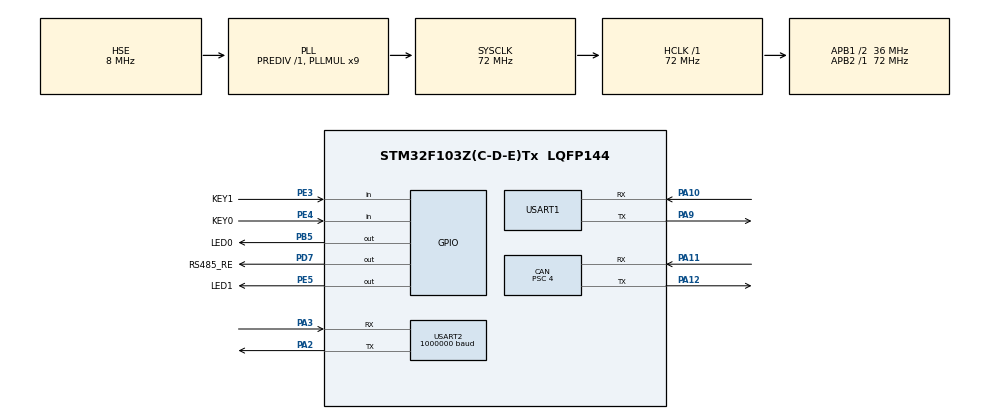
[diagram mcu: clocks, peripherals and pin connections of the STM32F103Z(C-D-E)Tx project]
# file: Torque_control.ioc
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CAN.ABOM=ENABLE
CAN.BS1=CAN_BS1_7TQ
CAN.CalculateBaudRate=1000000
CAN.CalculateTimeBit=1000
CAN.CalculateTimeQuantum=111.11111111111111
CAN.NART=ENABLE
CAN.Prescaler=4
Dma.Request0=USART2_RX
Dma.USART2_RX.0.Direction=DMA_PERIPH_TO_MEMORY
Dma.USART2_RX.0.Instance=DMA1_Channel6
Dma.USART2_RX.0.MemDataAlignment=DMA_MDATAALIGN_BYTE
Dma.USART2_RX.0.MemInc=DMA_MINC_ENABLE
Dma.USART2_RX.0.Mode=DMA_NORMAL
Dma.USART2_RX.0.PeriphDataAlignment=DMA_PDATAALIGN_BYTE
Dma.USART2_RX.0.PeriphInc=DMA_PINC_DISABLE
Dma.USART2_RX.0.Priority=DMA_PRIORITY_LOW
Mcu.Family=STM32F1
Mcu.Name=STM32F103Z(C-D-E)Tx
Mcu.Package=LQFP144
NVIC.DMA1_Channel6_IRQn=true\:0\:0\:false\:false\:true\:false\:true\:true
NVIC.PriorityGroup=NVIC_PRIORITYGROUP_4
NVIC.TIM3_IRQn=true\:1\:0\:true\:false\:true\:true\:true\:true
NVIC.USART1_IRQn=true\:1\:0\:true\:false\:true\:true\:true\:true
NVIC.USART2_IRQn=true\:0\:0\:true\:false\:true\:false\:true\:true
NVIC.USB_LP_CAN1_RX0_IRQn=true\:0\:0\:true\:false\:true\:true\:true\:true
OSC_IN.Mode=HSE-External-Oscillator
OSC_IN.Signal=RCC_OSC_IN
OSC_OUT.Mode=HSE-External-Oscillator
OSC_OUT.Signal=RCC_OSC_OUT
PA10.Mode=Asynchronous
PA10.Signal=USART1_RX
PA11.Mode=CAN_Activate
PA11.Signal=CAN_RX
PA12.Mode=CAN_Activate
PA12.Signal=CAN_TX
PA13.Mode=Serial_Wire
PA13.Signal=SYS_JTMS-SWDIO
PA14.Mode=Serial_Wire
PA14.Signal=SYS_JTCK-SWCLK
PA2.Mode=Asynchronous
PA2.Signal=USART2_TX
PA3.Mode=Asynchronous
PA3.Signal=USART2_RX
PA9.Mode=Asynchronous
PA9.Signal=USART1_TX
PB5.GPIO_Label=LED0
PB5.GPIO_PuPd=GPIO_PULLUP
PB5.PinState=GPIO_PIN_SET
PB5.Signal=GPIO_Output
PC14-OSC32_IN.Mode=LSE-External-Oscillator
PC14-OSC32_IN.Signal=RCC_OSC32_IN
PC15-OSC32_OUT.Mode=LSE-External-Oscillator
PC15-OSC32_OUT.Signal=RCC_OSC32_OUT
PD7.GPIO_Label=RS485_RE
PD7.GPIO_PuPd=GPIO_PULLDOWN
PD7.Signal=GPIO_Output
PE3.GPIO_Label=KEY1
PE3.GPIO_Mode=GPIO_MODE_INPUT
PE3.GPIO_PuPd=GPIO_PULLUP
PE3.Signal=GPIO_Input
PE4.GPIO_Label=KEY0
PE4.GPIO_PuPd=GPIO_PULLUP
PE4.Signal=GPIO_Input
PE5.GPIO_Label=LED1
PE5.GPIO_PuPd=GPIO_PULLUP
PE5.PinState=GPIO_PIN_SET
PE5.Signal=GPIO_Output
ProjectManager.HeapSize=0x200
ProjectManager.StackSize=0x400
ProjectManager.TargetToolchain=MDK-ARM V5.32
RCC.AHBFreq_Value=72000000
RCC.APB1CLKDivider=RCC_HCLK_DIV2
RCC.APB1Freq_Value=36000000
RCC.APB1TimFreq_Value=72000000
RCC.APB2Freq_Value=72000000
RCC.APB2TimFreq_Value=72000000
RCC.HCLKFreq_Value=72000000
RCC.PLLMUL=RCC_PLL_MUL9
RCC.PLLSourceVirtual=RCC_PLLSOURCE_HSE
RCC.SYSCLKFreq_VALUE=72000000
RCC.SYSCLKSource=RCC_SYSCLKSOURCE_PLLCLK
RCC.USBFreq_Value=72000000
TIM3.AutoReloadPreload=TIM_AUTORELOAD_PRELOAD_ENABLE
TIM3.Period=10000-1
TIM3.Prescaler=72-1
USART1.VirtualMode=VM_ASYNC
USART2.BaudRate=1000000
USART2.VirtualMode=VM_ASYNC
USART2.WordLength=WORDLENGTH_8B
VP_TIM3_VS_ClockSourceINT.Mode=Internal
board=custom

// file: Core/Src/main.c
/* USER CODE BEGIN Header */
/**
  ******************************************************************************
  * @file           : main.c
  * @brief          : Main program body
  ******************************************************************************
  * @attention
  *
  * Copyright (c) 2026 STMicroelectronics.
  * All rights reserved.
  *
  * This software is licensed under terms that can be found in the LICENSE file
  * in the root directory of this software component.
  * If no LICENSE file comes with this software, it is provided AS-IS.
  *
  ******************************************************************************
  */
/* USER CODE END Header */
#include "main.h"
#include "can.h"
#include "dma.h"
#include "tim.h"
#include "usart.h"
#include "gpio.h"

/* USER CODE BEGIN Includes */
#include "app_user.h"
#include "app_nj70.h"
#include "app_joint.h"
/* USER CODE END Includes */

void SystemClock_Config(void);

int main(void)
{

  /* MCU Configuration--------------------------------------------------------*/

  /* Reset of all peripherals, Initializes the Flash interface and the Systick. */
  HAL_Init();

  /* Configure the system clock */
  SystemClock_Config();

  /* Initialize all configured peripherals */
  MX_GPIO_Init();
  MX_DMA_Init();
  MX_USART2_UART_Init();
  MX_USART1_UART_Init();
  MX_CAN_Init();
  MX_TIM3_Init();
  /* USER CODE BEGIN 2 */
	Bsp_Can_Init();
	Dev_Joint_Init(1);
	Dev_NJ70_Init(rx_buffer, MAX_RX_BUFFER_SIZE);
  /* USER CODE END 2 */

  /* Infinite loop */
  /* USER CODE BEGIN WHILE */
  while (1)
  {
		App_Led_Task();
		App_Key_Task();
		App_NJ70_Task();
		App_Joint_Task();
		App_Joint_Adm_Task();        /* 导纳环：状态机 + PP 换点 + 发帧（ISR 里只算控制量） */
		//App_Joint_GravScan_Task(); /* PP 8 点扫角，标定重力矩时打开 */

    /* USER CODE END WHILE */

  }
}

void SystemClock_Config(void)
{
  RCC_OscInitTypeDef RCC_OscInitStruct = {0};
  RCC_ClkInitTypeDef RCC_ClkInitStruct = {0};

  /** Initializes the RCC Oscillators according to the specified parameters
  * in the RCC_OscInitTypeDef structure.
  */
  RCC_OscInitStruct.OscillatorType = RCC_OSCILLATORTYPE_HSE;
  RCC_OscInitStruct.HSEState = RCC_HSE_ON;
  RCC_OscInitStruct.HSEPredivValue = RCC_HSE_PREDIV_DIV1;
  RCC_OscInitStruct.HSIState = RCC_HSI_ON;
  RCC_OscInitStruct.PLL.PLLState = RCC_PLL_ON;
  RCC_OscInitStruct.PLL.PLLSource = RCC_PLLSOURCE_HSE;
  RCC_OscInitStruct.PLL.PLLMUL = RCC_PLL_MUL9;
  if (HAL_RCC_OscConfig(&RCC_OscInitStruct) != HAL_OK)
  {
    Error_Handler();
  }

  /** Initializes the CPU, AHB and APB buses clocks
  */
  RCC_ClkInitStruct.ClockType = RCC_CLOCKTYPE_HCLK|RCC_CLOCKTYPE_SYSCLK
                              |RCC_CLOCKTYPE_PCLK1|RCC_CLOCKTYPE_PCLK2;
  RCC_ClkInitStruct.SYSCLKSource = RCC_SYSCLKSOURCE_PLLCLK;
  RCC_ClkInitStruct.AHBCLKDivider = RCC_SYSCLK_DIV1;
  RCC_ClkInitStruct.APB1CLKDivider = RCC_HCLK_DIV2;
  RCC_ClkInitStruct.APB2CLKDivider = RCC_HCLK_DIV1;

  if (HAL_RCC_ClockConfig(&RCC_ClkInitStruct, FLASH_LATENCY_2) != HAL_OK)
  {
    Error_Handler();
  }
}

void Error_Handler(void)
{
  __disable_irq();
  while (1)
  {
  }
}
